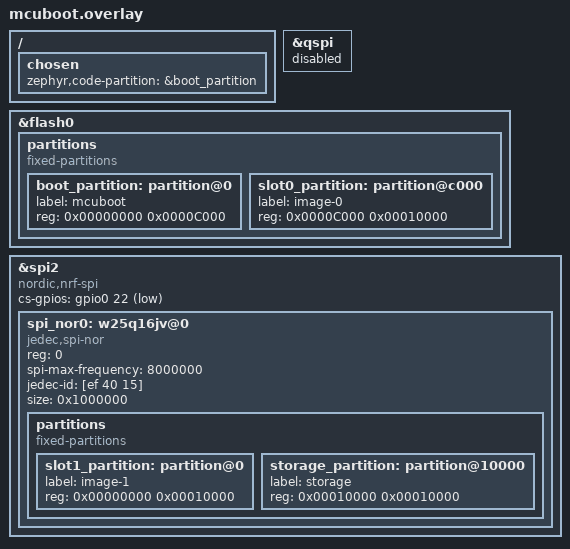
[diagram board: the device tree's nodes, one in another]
/*
 * SPDX-License-Identifier: Apache-2.0
 *
 * Devicetree overlay for MCUboot on nRF52840 with primary slot (slot0_partition)
 * in internal flash0 and secondary slot (slot1_partition) on external JEDEC
 * SPI NOR flash (Winbond W25Q16JV) attached to spi2 (0x40023000, CS# P0.22).
 */

&qspi {
    status = "disabled";
};

&flash0 {
    /delete-node/ partitions;

    partitions {
        compatible = "fixed-partitions";
        #address-cells = <1>;
        #size-cells = <1>;

        boot_partition: partition@0 {
            label = "mcuboot";
            reg = <0x00000000 0x0000C000>;
        };
        slot0_partition: partition@c000 {
            label = "image-0";
            reg = <0x0000C000 0x00010000>;
        };
    };
};

&spi2 {
    compatible = "nordic,nrf-spi";
    status = "okay";
    cs-gpios = <&gpio0 22 GPIO_ACTIVE_LOW>;

    spi_nor0: w25q16jv@0 {
        compatible = "jedec,spi-nor";
        reg = <0>;
        spi-max-frequency = <8000000>;
        jedec-id = [ef 40 15];
        size = <0x1000000>;

        partitions {
            compatible = "fixed-partitions";
            #address-cells = <1>;
            #size-cells = <1>;

            slot1_partition: partition@0 {
                label = "image-1";
                reg = <0x00000000 0x00010000>;
            };
            storage_partition: partition@10000 {
                label = "storage";
                reg = <0x00010000 0x00010000>;
            };
        };
    };
};

/ {
    chosen {
        zephyr,code-partition = &boot_partition;
    };
};
